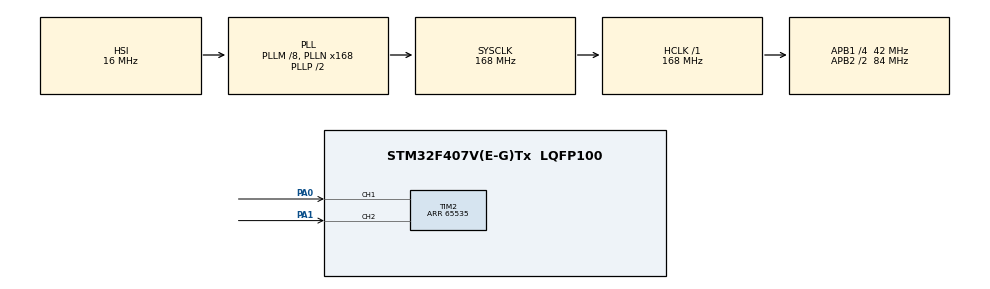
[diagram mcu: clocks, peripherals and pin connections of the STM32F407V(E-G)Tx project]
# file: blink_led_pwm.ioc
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Mcu.Family=STM32F4
Mcu.Name=STM32F407V(E-G)Tx
Mcu.Package=LQFP100
NVIC.PriorityGroup=NVIC_PRIORITYGROUP_0
NVIC.TIM2_IRQn=true\:0\:0\:false\:false\:true\:true\:true\:true
PA0-WKUP.Signal=S_TIM2_CH1_ETR
PA1.Signal=S_TIM2_CH2
ProjectManager.HeapSize=0x200
ProjectManager.StackSize=0x400
ProjectManager.TargetToolchain=Makefile
RCC.48MHZClocksFreq_Value=48000000
RCC.AHBFreq_Value=168000000
RCC.APB1CLKDivider=RCC_HCLK_DIV4
RCC.APB1Freq_Value=42000000
RCC.APB1TimFreq_Value=84000000
RCC.APB2CLKDivider=RCC_HCLK_DIV2
RCC.APB2Freq_Value=84000000
RCC.APB2TimFreq_Value=168000000
RCC.CortexFreq_Value=168000000
RCC.HCLKFreq_Value=168000000
RCC.HSE_VALUE=8000000
RCC.HSI_VALUE=16000000
RCC.LSE_VALUE=32768
RCC.PLLM=8
RCC.PLLN=168
RCC.PLLQ=7
RCC.SYSCLKFreq_VALUE=168000000
RCC.SYSCLKSource=RCC_SYSCLKSOURCE_PLLCLK
RCC.VCOOutputFreq_Value=336000000
SH.S_TIM2_CH1_ETR.0=TIM2_CH1,Encoder_Interface
SH.S_TIM2_CH2.0=TIM2_CH2,Encoder_Interface
TIM2.AutoReloadPreload=TIM_AUTORELOAD_PRELOAD_ENABLE
TIM2.EncoderMode=TIM_ENCODERMODE_TI12
TIM2.Period=65535
board=STM32F407G-DISC1

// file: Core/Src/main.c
/* USER CODE BEGIN Header */
/**
  ******************************************************************************
  * @file           : main.c
  * @brief          : Main program body
  ******************************************************************************
  * @attention
  *
  * Copyright (c) 2023 STMicroelectronics.
  * All rights reserved.
  *
  * This software is licensed under terms that can be found in the LICENSE file
  * in the root directory of this software component.
  * If no LICENSE file comes with this software, it is provided AS-IS.
  *
  ******************************************************************************
  */
/* USER CODE END Header */
#include "main.h"
#include "tim.h"
#include "gpio.h"

/* USER CODE BEGIN Includes */
#include <stdio.h>
/* USER CODE END Includes */

void SystemClock_Config(void);

/* USER CODE BEGIN 0 */
uint16_t valueRead;
int i = 0;
int control = 0;
// void HAL_GPIO_EXTI_Callback(uint16_t GPIO_Pin)
// {
//     if(GPIO_Pin == GPIO_PIN_7)
//     {
//       if((HAL_GPIO_ReadPin(GPIOA,GPIO_PIN_7) == GPIO_PIN_SET && HAL_GPIO_ReadPin(GPIOA,GPIO_PIN_6) == GPIO_PIN_RESET) ||
//       (HAL_GPIO_ReadPin(GPIOA,GPIO_PIN_6) == GPIO_PIN_SET && HAL_GPIO_ReadPin(GPIOA,GPIO_PIN_7) == GPIO_PIN_RESET))
//       {valueRead ++;}
//       else if((HAL_GPIO_ReadPin(GPIOA,GPIO_PIN_7) == GPIO_PIN_SET && HAL_GPIO_ReadPin(GPIOA,GPIO_PIN_6) == GPIO_PIN_SET) ||
//       (HAL_GPIO_ReadPin(GPIOA,GPIO_PIN_6) == GPIO_PIN_RESET && HAL_GPIO_ReadPin(GPIOA,GPIO_PIN_7) == GPIO_PIN_RESET))
//       {valueRead --; }
//     }
//     if(GPIO_Pin == GPIO_PIN_6)
//     {
//       if((HAL_GPIO_ReadPin(GPIOA,GPIO_PIN_7) == GPIO_PIN_SET && HAL_GPIO_ReadPin(GPIOA,GPIO_PIN_6) == GPIO_PIN_RESET) ||
//       (HAL_GPIO_ReadPin(GPIOA,GPIO_PIN_6) == GPIO_PIN_SET && HAL_GPIO_ReadPin(GPIOA,GPIO_PIN_7) == GPIO_PIN_RESET))
//       {valueRead --;}
//       else if((HAL_GPIO_ReadPin(GPIOA,GPIO_PIN_7) == GPIO_PIN_SET && HAL_GPIO_ReadPin(GPIOA,GPIO_PIN_6) == GPIO_PIN_SET) ||
//       (HAL_GPIO_ReadPin(GPIOA,GPIO_PIN_6) == GPIO_PIN_RESET && HAL_GPIO_ReadPin(GPIOA,GPIO_PIN_7) == GPIO_PIN_RESET))
//       {valueRead ++; }
//     }
// }
/* USER CODE END 0 */

int main(void)
{

  /* MCU Configuration--------------------------------------------------------*/

  /* Reset of all peripherals, Initializes the Flash interface and the Systick. */
  HAL_Init();

  /* Configure the system clock */
  SystemClock_Config();

  /* Initialize all configured peripherals */
  MX_GPIO_Init();
  MX_TIM2_Init();
  /* USER CODE BEGIN 2 */
  //HAL_TIM_Encoder_Start_IT(&htim2, TIM_CHANNEL_ALL);
  HAL_Delay(1000);

  /* USER CODE END 2 */

  /* Infinite loop */
  /* USER CODE BEGIN WHILE */
  while (1)
  {
    HAL_GPIO_TogglePin(GPIOD,GPIO_PIN_15);
    //  if(i<= 255 && control == 0)
    //  {
    //   i+=20;
    //  }
    //  else{
    //   control = 1;
    //  }
    //  if(i >= 0 && control == 1){
    //   i-=20;
    //  }
    //  else
    //  {
    //   control = 0;
    //  }

    // HAL_ADC_Start(&hadc1);
    // if(HAL_ADC_PollForConversion(&hadc1, 10)== HAL_OK)
    // {
    //   valueRead = HAL_ADC_GetValue(&hadc1);

    // }
    // HAL_ADC_Stop(&hadc1);
    //TIM2->CCR1 = valueRead;
    //valueRead=(uint16_t)htim2.Instance->CNT;
    printf("test \n");
    //printf(" analog read: %u \n", valueRead );
    HAL_Delay(100);
    /* USER CODE END WHILE */

  }
}

void SystemClock_Config(void)
{
  RCC_OscInitTypeDef RCC_OscInitStruct = {0};
  RCC_ClkInitTypeDef RCC_ClkInitStruct = {0};

  /** Configure the main internal regulator output voltage
  */
  __HAL_RCC_PWR_CLK_ENABLE();
  __HAL_PWR_VOLTAGESCALING_CONFIG(PWR_REGULATOR_VOLTAGE_SCALE1);

  /** Initializes the RCC Oscillators according to the specified parameters
  * in the RCC_OscInitTypeDef structure.
  */
  RCC_OscInitStruct.OscillatorType = RCC_OSCILLATORTYPE_HSI;
  RCC_OscInitStruct.HSIState = RCC_HSI_ON;
  RCC_OscInitStruct.HSICalibrationValue = RCC_HSICALIBRATION_DEFAULT;
  RCC_OscInitStruct.PLL.PLLState = RCC_PLL_ON;
  RCC_OscInitStruct.PLL.PLLSource = RCC_PLLSOURCE_HSI;
  RCC_OscInitStruct.PLL.PLLM = 8;
  RCC_OscInitStruct.PLL.PLLN = 168;
  RCC_OscInitStruct.PLL.PLLP = RCC_PLLP_DIV2;
  RCC_OscInitStruct.PLL.PLLQ = 7;
  if (HAL_RCC_OscConfig(&RCC_OscInitStruct) != HAL_OK)
  {
    Error_Handler();
  }

  /** Initializes the CPU, AHB and APB buses clocks
  */
  RCC_ClkInitStruct.ClockType = RCC_CLOCKTYPE_HCLK|RCC_CLOCKTYPE_SYSCLK
                              |RCC_CLOCKTYPE_PCLK1|RCC_CLOCKTYPE_PCLK2;
  RCC_ClkInitStruct.SYSCLKSource = RCC_SYSCLKSOURCE_PLLCLK;
  RCC_ClkInitStruct.AHBCLKDivider = RCC_SYSCLK_DIV1;
  RCC_ClkInitStruct.APB1CLKDivider = RCC_HCLK_DIV4;
  RCC_ClkInitStruct.APB2CLKDivider = RCC_HCLK_DIV2;

  if (HAL_RCC_ClockConfig(&RCC_ClkInitStruct, FLASH_LATENCY_5) != HAL_OK)
  {
    Error_Handler();
  }
}

void Error_Handler(void)
{
  __disable_irq();
  while (1)
  {
  }
}
